# XMC4300 register map
Vendor: Infineon; File version: 1.0.4 (Reference Manual v1.0)
CPU: CM4 r2p0, little endian, MPU, FPU, 6 interrupt priority bits
Registers are 32-bit, read-write, reset 0x0 unless marked. A register's access mark holds for its fields unless they carry their own. Offsets are from the block's base; [hi:lo] are bit positions; 'fields as' and 'values as' point back to an identical list.

## SCU_GENERAL — System Control Unit
Base 0x50004000
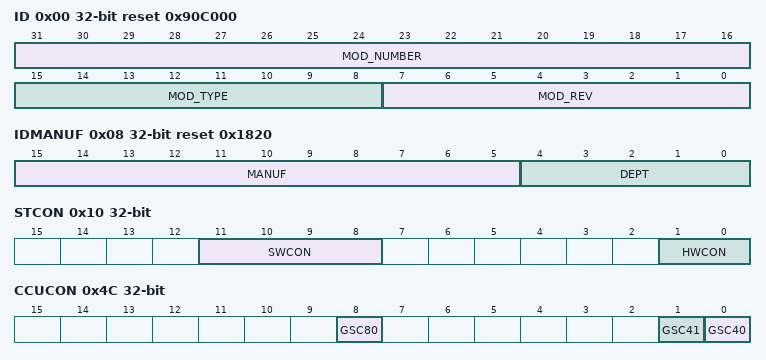
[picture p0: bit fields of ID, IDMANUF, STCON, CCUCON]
0x00 ID ro reset 0x90C000 (reset mask 0xFFFFFF00) — SCU Module ID Register
  [31:16] MOD_NUMBER — Module Number
  [15:8] MOD_TYPE — Module Type
  [7:0] MOD_REV — Module Revision
0x04 IDCHIP ro reset not defined — Chip ID Register
  [31:0] IDCHIP — Chip ID
0x08 IDMANUF ro reset 0x1820 — Manufactory ID Register
  [15:5] MANUF — Manufacturer Identification Number
  [4:0] DEPT — Department Identification Number
0x10 STCON access per field — Startup Configuration Register
  [11:8] SWCON rw — SW Configuration
    0=Const_0000 (Normal mode, boot from Boot ROM); 1=Const_0001 (ASC BSL enabled); 2=Const_0010 (BMI customized boot enabled); 3=Const_0011 (CAN BSL enabled); 4=Const_0100 (Boot from Code SRAM); 8=Const_1000 (Boot from alternate Flash Address 0); 12=Const_1100 (Boot from alternate Flash Address 1); 14=Const_1110 (Enable fallback Alternate Boot Mode (ABM))
  [1:0] HWCON ro — HW Configuration
    0=Const_00 (Normal mode, JTAG); 1=Const_01 (ASC BSL enabled); 2=Const_10 (BMI customized boot enabled); 3=Const_11 (CAN BSL enabled)
0x2C GPR0 — General Purpose Register 0
  [31:0] DAT — User Data
0x30 GPR1 — General Purpose Register 1
  [31:0] DAT — User Data
0x4C CCUCON — CCU Control Register
  [8] GSC80 — Global Start Control CCU80
  [1] GSC41 — Global Start Control CCU41
  [0] GSC40 — Global Start Control CCU40
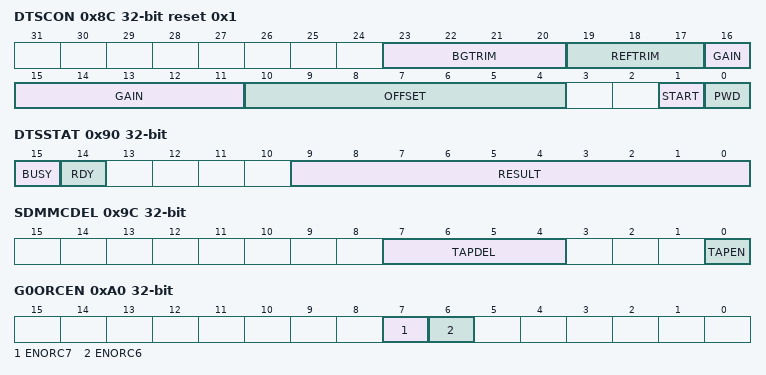
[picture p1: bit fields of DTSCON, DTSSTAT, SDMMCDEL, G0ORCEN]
0x8C DTSCON access per field reset 0x1 — Die Temperature Sensor Control Register
  [23:20] BGTRIM rw — Bandgap Trim Calibration Value
  [19:17] REFTRIM rw — Reference Trim Calibration Value
  [16:11] GAIN rw — Gain Calibration Value
  [10:4] OFFSET rw — Offset Calibration Value
  [1] START wo — Sensor Measurement Start
    0=Const_0 (No DTS measurement is started); 1=Const_1 (DTS measurement is started)
  [0] PWD rw — Sensor Power Down
    0=Const_0 (The DTS is powered); 1=Const_1 (The DTS is not powered)
0x90 DTSSTAT ro — Die Temperature Sensor Status Register
  [15] BUSY — Sensor Busy Status
    0=Const_0 (not busy); 1=Const_1 (busy)
  [14] RDY — Sensor Ready Status
    0=Const_0 (The DTS is not ready); 1=Const_1 (The DTS is ready)
  [9:0] RESULT — Result of the DTS Measurement
0x9C SDMMCDEL — SD-MMC Delay Control Register
  [7:4] TAPDEL — Number of Delay Elements Select
  [0] TAPEN — Enable delay on the CMD/DAT out lines
    0=Disabled; 1=Enabled
0xA0 G0ORCEN — Out of Range Comparator Enable Register 0
  [7] ENORC7 — Enable Out of Range Comparator, Channel 7
    0=Const_0 (Disabled); 1=Const_1 (Enabled)
  [6] ENORC6 — Enable Out of Range Comparator, Channel 6
    0=Const_0 (Disabled); 1=Const_1 (Enabled)
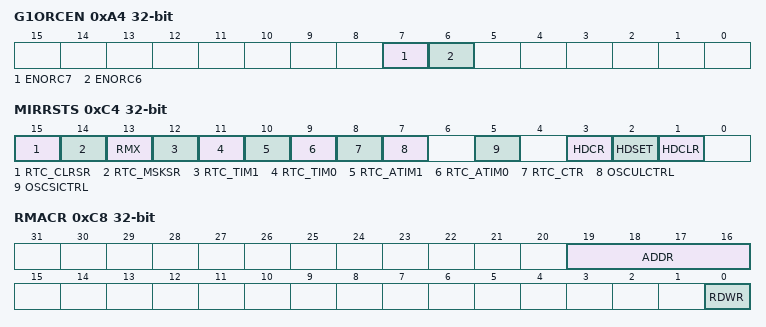
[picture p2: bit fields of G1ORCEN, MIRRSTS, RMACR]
0xA4 G1ORCEN — Out of Range Comparator Enable Register 1
  fields as G0ORCEN
0xC4 MIRRSTS ro — Mirror Write Status Register
  [all] fields
    0=Const_0 (Ready); 1=Const_1 (Busy)
  [15] RTC_CLRSR — RTC CLRSR Mirror Register Write Status
  [14] RTC_MSKSR — RTC MSKSSR Mirror Register Write Status
  [13] RMX — Retention Memory Access Register Update Status
  [12] RTC_TIM1 — RTC TIM1 Mirror Register Write Status
  [11] RTC_TIM0 — RTC TIM0 Mirror Register Write Status
  [10] RTC_ATIM1 — RTC ATIM1 Mirror Register Write Status
  [9] RTC_ATIM0 — RTC ATIM0 Mirror Register Write Status
  [8] RTC_CTR — RTC CTR Mirror Register Write Status
  [7] OSCULCTRL — OSCULCTRL Mirror Register Write Status
  [5] OSCSICTRL — OSCSICTRL Mirror Register Write Status
  [3] HDCR — HDCR Mirror Register Write Status
  [2] HDSET — HDSET Mirror Register Write Status
  [1] HDCLR — HDCLR Mirror Register Write Status
0xC8 RMACR — Retention Memory Access Control Register
  [19:16] ADDR — Hibernate Retention Memory Register Address Select
  [0] RDWR — Hibernate Retention Memory Register Update Control
    0=Const_0 (transfer data from Retention Memory in Hibernate domain to RMDATA register); 1=Const_1 (transfer data from RMDATA into Retention Memory in Hibernate domain)
0xCC RMDATA — Retention Memory Access Data Register
  [31:0] DATA — Hibernate Retention Memory Data
